# ESP32-P4 register map
Vendor: ESPRESSIF SYSTEMS (SHANGHAI) CO., LTD.; Series: ESP32 P-Series; File version: 2
CPU: RV32IMAFC r0p0, little endian, no MPU, FPU, 0 interrupt priority bits
Address unit: 32 bits
Registers are 32-bit, read-write, reset 0x0 unless marked. A register's access mark holds for its fields unless they carry their own. Offsets are from the block's base; [hi:lo] are bit positions; {n}, {i} and the like mark numbered series.

## MIPI_CSI_HOST — MIPI Camera Interface Host
Base 0x5009F000
0x00 VERSION ro reset 0x3135302A
0x04 N_LANES reset 0x1
  [2:0] N_LANES
0x08 CSI2_RESETN
  [0] CSI2_RESETN
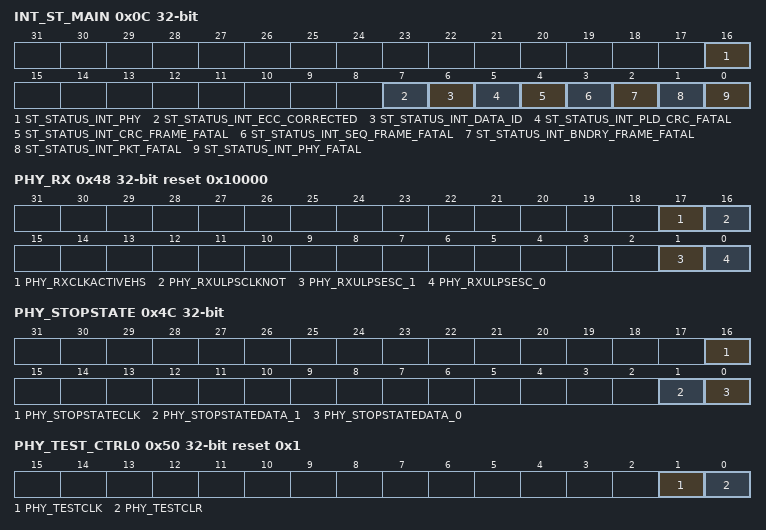
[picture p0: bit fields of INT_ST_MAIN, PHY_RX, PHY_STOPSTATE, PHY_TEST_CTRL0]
0x0C INT_ST_MAIN ro
  [16] ST_STATUS_INT_PHY, [7] ST_STATUS_INT_ECC_CORRECTED, [6] ST_STATUS_INT_DATA_ID, [5] ST_STATUS_INT_PLD_CRC_FATAL, [4] ST_STATUS_INT_CRC_FRAME_FATAL, [3] ST_STATUS_INT_SEQ_FRAME_FATAL, [2] ST_STATUS_INT_BNDRY_FRAME_FATAL, [1] ST_STATUS_INT_PKT_FATAL, [0] ST_STATUS_INT_PHY_FATAL
0x40 PHY_SHUTDOWNZ
  [0] PHY_SHUTDOWNZ
0x44 DPHY_RSTZ
  [0] DPHY_RSTZ
0x48 PHY_RX ro reset 0x10000
  [17] PHY_RXCLKACTIVEHS, [16] PHY_RXULPSCLKNOT, [1] PHY_RXULPSESC_1, [0] PHY_RXULPSESC_0
0x4C PHY_STOPSTATE ro
  [16] PHY_STOPSTATECLK, [1] PHY_STOPSTATEDATA_1, [0] PHY_STOPSTATEDATA_0
0x50 PHY_TEST_CTRL0 reset 0x1
  [1] PHY_TESTCLK, [0] PHY_TESTCLR
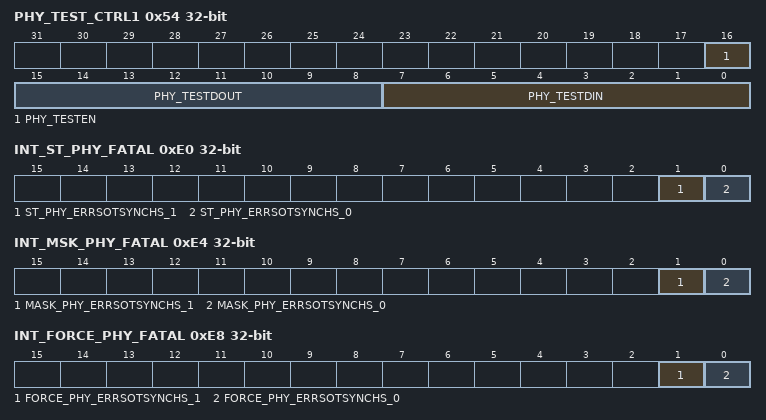
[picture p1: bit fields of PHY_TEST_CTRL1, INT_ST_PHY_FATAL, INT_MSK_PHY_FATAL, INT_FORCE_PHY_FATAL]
0x54 PHY_TEST_CTRL1 access per field
  [16] PHY_TESTEN rw, [15:8] PHY_TESTDOUT ro, [7:0] PHY_TESTDIN rw
0xC8 VC_EXTENSION
  [0] VCX
0xCC PHY_CAL ro
  [0] RXSKEWCALHS
0xE0 INT_ST_PHY_FATAL ro
  [1] ST_PHY_ERRSOTSYNCHS_1, [0] ST_PHY_ERRSOTSYNCHS_0
0xE4 INT_MSK_PHY_FATAL
  [1] MASK_PHY_ERRSOTSYNCHS_1, [0] MASK_PHY_ERRSOTSYNCHS_0
0xE8 INT_FORCE_PHY_FATAL
  [1] FORCE_PHY_ERRSOTSYNCHS_1, [0] FORCE_PHY_ERRSOTSYNCHS_0
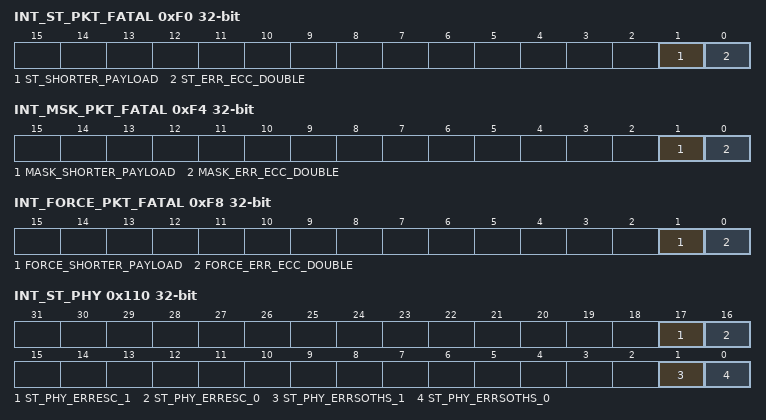
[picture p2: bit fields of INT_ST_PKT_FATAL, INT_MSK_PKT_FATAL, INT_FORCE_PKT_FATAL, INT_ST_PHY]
0xF0 INT_ST_PKT_FATAL ro
  [1] ST_SHORTER_PAYLOAD, [0] ST_ERR_ECC_DOUBLE
0xF4 INT_MSK_PKT_FATAL
  [1] MASK_SHORTER_PAYLOAD, [0] MASK_ERR_ECC_DOUBLE
0xF8 INT_FORCE_PKT_FATAL
  [1] FORCE_SHORTER_PAYLOAD, [0] FORCE_ERR_ECC_DOUBLE
0x110 INT_ST_PHY ro
  [17] ST_PHY_ERRESC_1, [16] ST_PHY_ERRESC_0, [1] ST_PHY_ERRSOTHS_1, [0] ST_PHY_ERRSOTHS_0
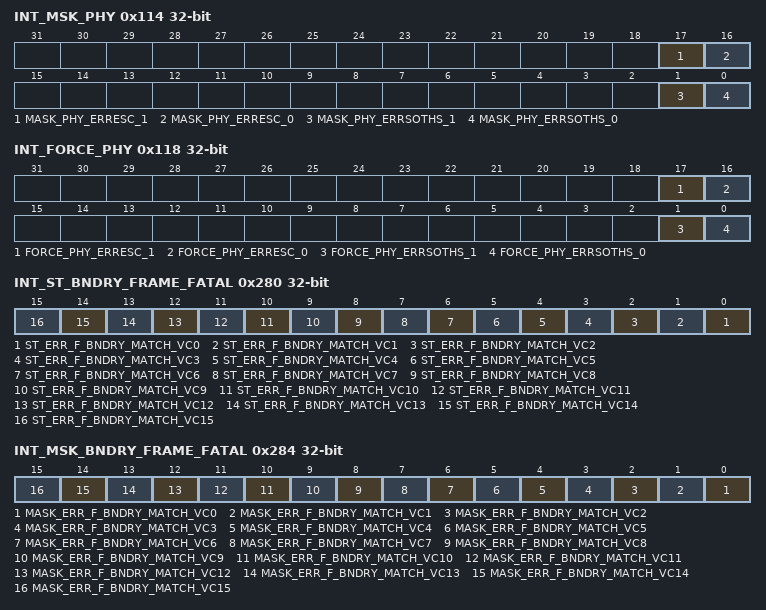
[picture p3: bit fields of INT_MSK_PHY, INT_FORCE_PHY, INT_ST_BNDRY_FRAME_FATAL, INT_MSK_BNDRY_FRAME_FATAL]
0x114 INT_MSK_PHY
  [17] MASK_PHY_ERRESC_1, [16] MASK_PHY_ERRESC_0, [1] MASK_PHY_ERRSOTHS_1, [0] MASK_PHY_ERRSOTHS_0
0x118 INT_FORCE_PHY
  [17] FORCE_PHY_ERRESC_1, [16] FORCE_PHY_ERRESC_0, [1] FORCE_PHY_ERRSOTHS_1, [0] FORCE_PHY_ERRSOTHS_0
0x280 INT_ST_BNDRY_FRAME_FATAL ro
  [n] ST_ERR_F_BNDRY_MATCH_VC{n} (n=0..15)
0x284 INT_MSK_BNDRY_FRAME_FATAL
  [n] MASK_ERR_F_BNDRY_MATCH_VC{n} (n=0..15)
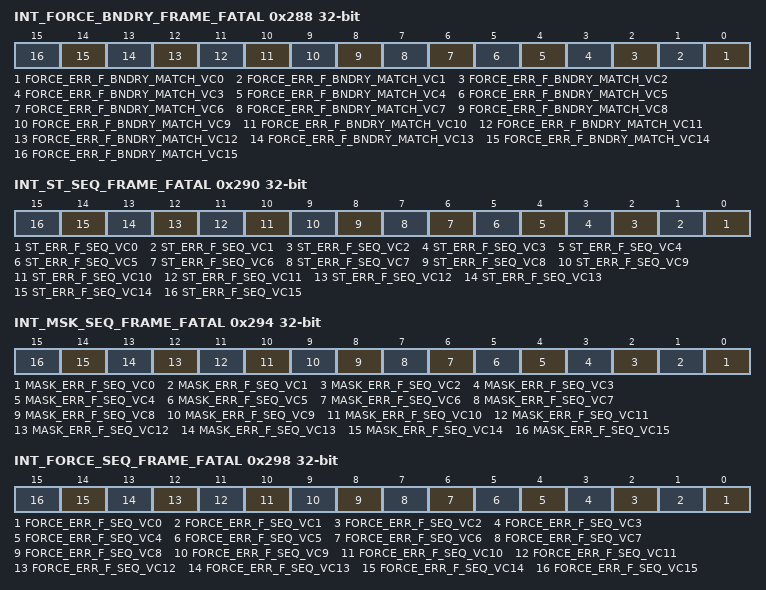
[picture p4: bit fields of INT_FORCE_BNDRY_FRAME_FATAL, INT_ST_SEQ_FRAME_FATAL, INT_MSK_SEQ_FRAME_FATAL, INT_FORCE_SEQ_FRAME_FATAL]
0x288 INT_FORCE_BNDRY_FRAME_FATAL
  [n] FORCE_ERR_F_BNDRY_MATCH_VC{n} (n=0..15)
0x290 INT_ST_SEQ_FRAME_FATAL ro
  [n] ST_ERR_F_SEQ_VC{n} (n=0..15)
0x294 INT_MSK_SEQ_FRAME_FATAL
  [n] MASK_ERR_F_SEQ_VC{n} (n=0..15)
0x298 INT_FORCE_SEQ_FRAME_FATAL
  [n] FORCE_ERR_F_SEQ_VC{n} (n=0..15)
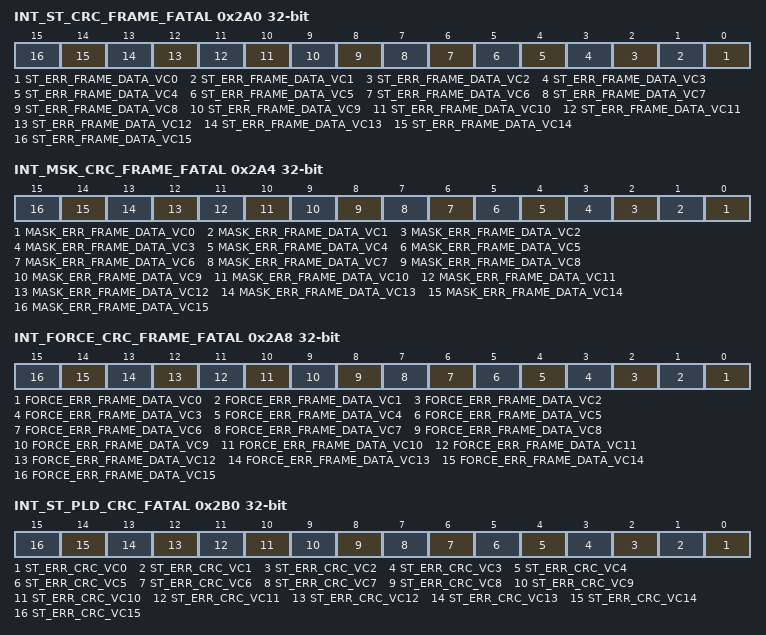
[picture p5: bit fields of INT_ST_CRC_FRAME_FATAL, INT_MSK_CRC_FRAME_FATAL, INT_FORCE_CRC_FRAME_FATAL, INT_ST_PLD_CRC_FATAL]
0x2A0 INT_ST_CRC_FRAME_FATAL ro
  [n] ST_ERR_FRAME_DATA_VC{n} (n=0..15)
0x2A4 INT_MSK_CRC_FRAME_FATAL
  [n] MASK_ERR_FRAME_DATA_VC{n} (n=0..15)
0x2A8 INT_FORCE_CRC_FRAME_FATAL
  [n] FORCE_ERR_FRAME_DATA_VC{n} (n=0..15)
0x2B0 INT_ST_PLD_CRC_FATAL ro
  [n] ST_ERR_CRC_VC{n} (n=0..15)
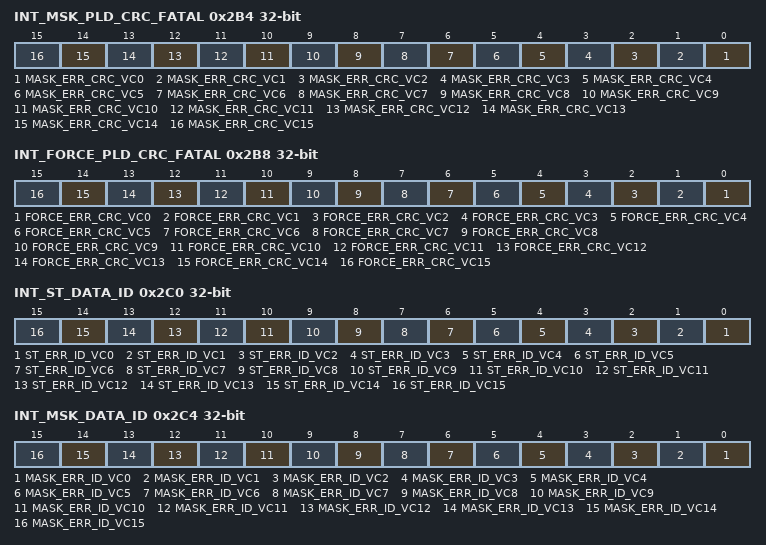
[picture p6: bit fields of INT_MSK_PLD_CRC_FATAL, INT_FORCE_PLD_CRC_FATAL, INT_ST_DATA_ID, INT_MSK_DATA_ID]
0x2B4 INT_MSK_PLD_CRC_FATAL
  [n] MASK_ERR_CRC_VC{n} (n=0..15)
0x2B8 INT_FORCE_PLD_CRC_FATAL
  [n] FORCE_ERR_CRC_VC{n} (n=0..15)
0x2C0 INT_ST_DATA_ID ro
  [n] ST_ERR_ID_VC{n} (n=0..15)
0x2C4 INT_MSK_DATA_ID
  [n] MASK_ERR_ID_VC{n} (n=0..15)
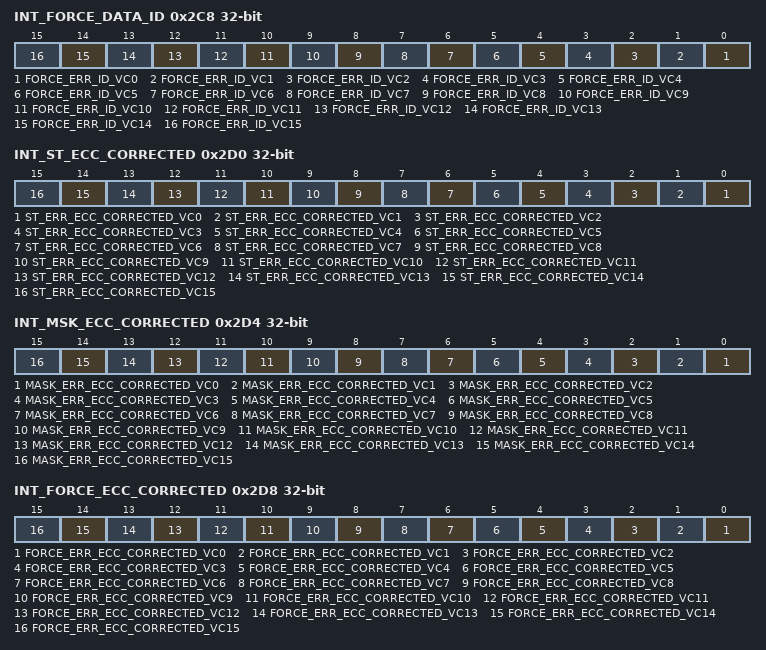
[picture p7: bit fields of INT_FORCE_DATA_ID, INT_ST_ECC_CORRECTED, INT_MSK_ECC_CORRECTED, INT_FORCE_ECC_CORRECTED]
0x2C8 INT_FORCE_DATA_ID
  [n] FORCE_ERR_ID_VC{n} (n=0..15)
0x2D0 INT_ST_ECC_CORRECTED ro
  [n] ST_ERR_ECC_CORRECTED_VC{n} (n=0..15)
0x2D4 INT_MSK_ECC_CORRECTED
  [n] MASK_ERR_ECC_CORRECTED_VC{n} (n=0..15)
0x2D8 INT_FORCE_ECC_CORRECTED
  [n] FORCE_ERR_ECC_CORRECTED_VC{n} (n=0..15)
0x300 SCRAMBLING
  [0] SCRAMBLE_ENABLE
0x304 SCRAMBLING_SEED1 reset 0x1008
  [15:0] SCRAMBLE_SEED_LANE1
0x308 SCRAMBLING_SEED2 reset 0x1188
  [15:0] SCRAMBLE_SEED_LANE2

## DS — Digital Signature
Base 0x50094000
{0x0+4i} Y_MEM[{i}] (i=0..127) access not given — memory that stores Y
{0x200+4i} M_MEM[{i}] (i=0..127) access not given — memory that stores M
{0x400+4i} RB_MEM[{i}] (i=0..127) access not given — memory that stores Rb
{0x600+4i} BOX_MEM[{i}] (i=0..11) access not given — memory that stores BOX
{0x630+4i} IV_MEM[{i}] (i=0..3) access not given — memory that stores IV
{0x800+4i} X_MEM[{i}] (i=0..127) access not given — memory that stores X
{0xA00+4i} Z_MEM[{i}] (i=0..127) access not given — memory that stores Z
0xE00 SET_START wo — DS start control register
  [0] SET_START — set this bit to start DS operation.
0xE04 SET_CONTINUE wo — DS continue control register
  [0] SET_CONTINUE — set this bit to continue DS operation.
0xE08 SET_FINISH wo — DS finish control register
  [0] SET_FINISH — Set this bit to finish DS process.
0xE0C QUERY_BUSY ro — DS query busy register
  [0] QUERY_BUSY — digital signature state. 1'b0: idle, 1'b1: busy
0xE10 QUERY_KEY_WRONG ro — DS query key-wrong counter register
  [3:0] QUERY_KEY_WRONG — digital signature key wrong counter
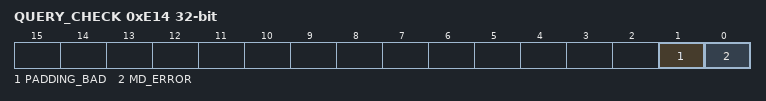
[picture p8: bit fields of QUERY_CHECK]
0xE14 QUERY_CHECK ro — DS query check result register
  [1] PADDING_BAD — padding checkout result. 1'b0: a good padding, 1'b1: a bad padding
  [0] MD_ERROR — MD checkout result. 1'b0: MD check pass, 1'b1: MD check fail
0xE20 DATE reset 0x20200618 — DS version control register
  [29:0] DATE — ds version information
